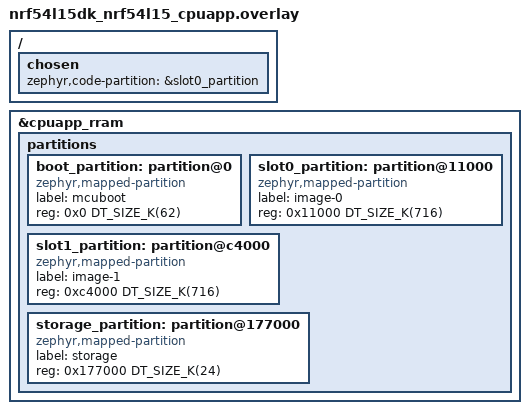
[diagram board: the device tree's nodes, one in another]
/*
 * Copyright (c) 2026 Nordic Semiconductor ASA
 *
 * SPDX-License-Identifier: LicenseRef-Nordic-5-Clause
 */

&cpuapp_rram {
	/delete-node/ partitions;

	partitions {
		ranges;
		#address-cells = <1>;
		#size-cells = <1>;

		boot_partition: partition@0 {
			compatible = "zephyr,mapped-partition";
			label = "mcuboot";
			reg = <0x0 DT_SIZE_K(62)>;
		};

		/* Gap from 10800 to 11000 (2 kB) */

		slot0_partition: partition@11000 {
			compatible = "zephyr,mapped-partition";
			label = "image-0";
			reg = <0x11000 DT_SIZE_K(716)>;
		};

		slot1_partition: partition@c4000 {
			compatible = "zephyr,mapped-partition";
			label = "image-1";
			reg = <0xc4000 DT_SIZE_K(716)>;
		};

		storage_partition: partition@177000 {
			compatible = "zephyr,mapped-partition";
			label = "storage";
			reg = <0x177000 DT_SIZE_K(24)>;
		};
	};
};

/ {
	chosen {
		zephyr,code-partition = &slot0_partition;
	};
};
